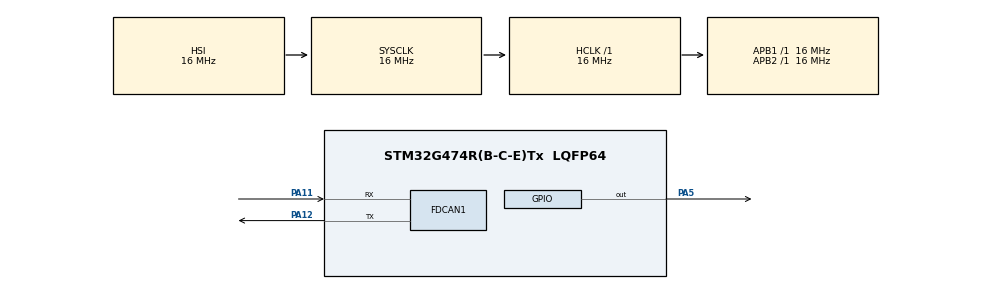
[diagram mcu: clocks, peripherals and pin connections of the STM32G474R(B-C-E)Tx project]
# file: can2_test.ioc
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FDCAN1.AutoRetransmission=ENABLE
FDCAN1.CalculateBaudRateNominal=250000
FDCAN1.CalculateTimeBitNominal=4000
FDCAN1.CalculateTimeQuantumNominal=125.0
FDCAN1.NominalPrescaler=2
FDCAN1.NominalSyncJumpWidth=4
FDCAN1.NominalTimeSeg1=25
FDCAN1.NominalTimeSeg2=6
FDCAN1.StdFiltersNbr=1
Mcu.Family=STM32G4
Mcu.Name=STM32G474R(B-C-E)Tx
Mcu.Package=LQFP64
NVIC.PriorityGroup=NVIC_PRIORITYGROUP_4
PA11.Mode=FDCAN_Activate
PA11.Signal=FDCAN1_RX
PA12.Mode=FDCAN_Activate
PA12.Signal=FDCAN1_TX
PA5.Signal=GPIO_Output
PA13.Mode=Serial_Wire
PA13.Signal=SYS_JTMS-SWDIO
PA14.Mode=Serial_Wire
PA14.Signal=SYS_JTCK-SWCLK
ProjectManager.HeapSize=0x200
ProjectManager.StackSize=0x400
ProjectManager.TargetToolchain=STM32CubeIDE
RCC.AHBFreq_Value=16000000
RCC.APB1Freq_Value=16000000
RCC.APB1TimFreq_Value=16000000
RCC.APB2Freq_Value=16000000
RCC.APB2TimFreq_Value=16000000
RCC.CortexFreq_Value=16000000
RCC.EXTERNAL_CLOCK_VALUE=12288000
RCC.HCLKFreq_Value=16000000
RCC.HSE_VALUE=8000000
RCC.HSI48_VALUE=48000000
RCC.HSI_VALUE=16000000
RCC.LSE_VALUE=32768
RCC.SYSCLKFreq_VALUE=16000000
RCC.USBFreq_Value=64000000
RCC.VCOOutputFreq_Value=128000000
VP_SYS_VS_DBSignals.Mode=DisableDeadBatterySignals
board=custom

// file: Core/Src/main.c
/* USER CODE BEGIN Header */
/**
  ******************************************************************************
  * @file           : main.c
  * @brief          : Main program body
  ******************************************************************************
  * @attention
  *
  * Copyright (c) 2026 STMicroelectronics.
  * All rights reserved.
  *
  * This software is licensed under terms that can be found in the LICENSE file
  * in the root directory of this software component.
  * If no LICENSE file comes with this software, it is provided AS-IS.
  *
  ******************************************************************************
  */
/* USER CODE END Header */
#include "main.h"

/* USER CODE BEGIN PD */
#define NODE_A  1  // G474 sends CAN pings to the F303.
/* USER CODE END PD */

FDCAN_HandleTypeDef hfdcan1;

/* USER CODE BEGIN PV */
volatile uint32_t canQueued = 0;
volatile uint32_t canCompleted = 0;
volatile uint32_t canLastError = 0;
volatile uint32_t canTxError = 0;
/* USER CODE END PV */

void SystemClock_Config(void);
static void MX_GPIO_Init(void);
static void MX_FDCAN1_Init(void);

int main(void)
{

  /* MCU Configuration--------------------------------------------------------*/

  /* Reset of all peripherals, Initializes the Flash interface and the Systick. */
  HAL_Init();

  /* Configure the system clock */
  SystemClock_Config();

  /* Initialize all configured peripherals */
  MX_GPIO_Init();
  MX_FDCAN1_Init();
  /* USER CODE BEGIN 2 */
  FDCAN_FilterTypeDef filter = {0};
  filter.IdType = FDCAN_STANDARD_ID;
  filter.FilterIndex = 0;
  filter.FilterType = FDCAN_FILTER_MASK;
  filter.FilterConfig = FDCAN_FILTER_TO_RXFIFO0;
  filter.FilterID1 = 0;
  filter.FilterID2 = 0;  // Accept all standard IDs

  if (HAL_FDCAN_ConfigFilter(&hfdcan1, &filter) != HAL_OK) Error_Handler();
  if (HAL_FDCAN_ConfigGlobalFilter(&hfdcan1,
          FDCAN_REJECT, FDCAN_REJECT,
          FDCAN_REJECT_REMOTE, FDCAN_REJECT_REMOTE) != HAL_OK) Error_Handler();
  if (HAL_FDCAN_Start(&hfdcan1) != HAL_OK) Error_Handler();

  FDCAN_TxHeaderTypeDef tx = {0};
  tx.IdType = FDCAN_STANDARD_ID;
  tx.TxFrameType = FDCAN_DATA_FRAME;
  tx.DataLength = FDCAN_DLC_BYTES_1;
  tx.ErrorStateIndicator = FDCAN_ESI_ACTIVE;
  tx.BitRateSwitch = FDCAN_BRS_OFF;
  tx.FDFormat = FDCAN_CLASSIC_CAN;
  tx.TxEventFifoControl = FDCAN_NO_TX_EVENTS;
  tx.MessageMarker = 0;

  uint8_t txData[1] = {0x55};
#if NODE_A
  uint32_t lastTx = HAL_GetTick();
#endif
  /* USER CODE END 2 */

  /* Infinite loop */
  while (1)
  {

    /* USER CODE BEGIN 3 */
#if NODE_A
if (HAL_GetTick() - lastTx >= 500) {
    lastTx = HAL_GetTick();
    tx.Identifier = 0x123;
    if (HAL_FDCAN_GetTxFifoFreeLevel(&hfdcan1) > 0) {
    	if (HAL_FDCAN_AddMessageToTxFifoQ(&hfdcan1, &tx, txData) == HAL_OK)
    	    canQueued++;
    }
}
#endif

if (HAL_FDCAN_GetRxFifoFillLevel(&hfdcan1, FDCAN_RX_FIFO0) > 0) {
    FDCAN_RxHeaderTypeDef rx;
    uint8_t rxData[8];

    if (HAL_FDCAN_GetRxMessage(&hfdcan1, FDCAN_RX_FIFO0,
                               &rx, rxData) == HAL_OK) {
#if NODE_A
        if (rx.Identifier == 0x124) {
            HAL_GPIO_TogglePin(GPIOA, GPIO_PIN_5); // Reply received from F303
        }
#else
        if (rx.Identifier == 0x123) {
            HAL_GPIO_TogglePin(GPIOA, GPIO_PIN_5); // Ping received
            tx.Identifier = 0x124;
            if (HAL_FDCAN_GetTxFifoFreeLevel(&hfdcan1) > 0) {
                HAL_FDCAN_AddMessageToTxFifoQ(&hfdcan1, &tx, txData);
            }
        }
#endif
    }
}
if (__HAL_FDCAN_GET_FLAG(&hfdcan1, FDCAN_FLAG_TX_COMPLETE)) {
    canCompleted++;
    __HAL_FDCAN_CLEAR_FLAG(&hfdcan1, FDCAN_FLAG_TX_COMPLETE);
}

FDCAN_ProtocolStatusTypeDef status;
FDCAN_ErrorCountersTypeDef errors;
if (HAL_FDCAN_GetProtocolStatus(&hfdcan1, &status) == HAL_OK)
    canLastError = status.LastErrorCode;
if (HAL_FDCAN_GetErrorCounters(&hfdcan1, &errors) == HAL_OK)
    canTxError = errors.TxErrorCnt;
HAL_Delay(1);
  }
  /* USER CODE END 3 */
}

void SystemClock_Config(void)
{
  RCC_OscInitTypeDef RCC_OscInitStruct = {0};
  RCC_ClkInitTypeDef RCC_ClkInitStruct = {0};

  /** Configure the main internal regulator output voltage
  */
  HAL_PWREx_ControlVoltageScaling(PWR_REGULATOR_VOLTAGE_SCALE1);

  /** Initializes the RCC Oscillators according to the specified parameters
  * in the RCC_OscInitTypeDef structure.
  */
  RCC_OscInitStruct.OscillatorType = RCC_OSCILLATORTYPE_HSI;
  RCC_OscInitStruct.HSIState = RCC_HSI_ON;
  RCC_OscInitStruct.HSICalibrationValue = RCC_HSICALIBRATION_DEFAULT;
  RCC_OscInitStruct.PLL.PLLState = RCC_PLL_NONE;
  if (HAL_RCC_OscConfig(&RCC_OscInitStruct) != HAL_OK)
  {
    Error_Handler();
  }

  /** Initializes the CPU, AHB and APB buses clocks
  */
  RCC_ClkInitStruct.ClockType = RCC_CLOCKTYPE_HCLK|RCC_CLOCKTYPE_SYSCLK
                              |RCC_CLOCKTYPE_PCLK1|RCC_CLOCKTYPE_PCLK2;
  RCC_ClkInitStruct.SYSCLKSource = RCC_SYSCLKSOURCE_HSI;
  RCC_ClkInitStruct.AHBCLKDivider = RCC_SYSCLK_DIV1;
  RCC_ClkInitStruct.APB1CLKDivider = RCC_HCLK_DIV1;
  RCC_ClkInitStruct.APB2CLKDivider = RCC_HCLK_DIV1;

  if (HAL_RCC_ClockConfig(&RCC_ClkInitStruct, FLASH_LATENCY_0) != HAL_OK)
  {
    Error_Handler();
  }
}

static void MX_FDCAN1_Init(void)
{

  hfdcan1.Instance = FDCAN1;
  hfdcan1.Init.ClockDivider = FDCAN_CLOCK_DIV1;
  hfdcan1.Init.FrameFormat = FDCAN_FRAME_CLASSIC;
  hfdcan1.Init.Mode = FDCAN_MODE_NORMAL;
  hfdcan1.Init.AutoRetransmission = ENABLE;
  hfdcan1.Init.TransmitPause = DISABLE;
  hfdcan1.Init.ProtocolException = DISABLE;
  hfdcan1.Init.NominalPrescaler = 2;
  hfdcan1.Init.NominalSyncJumpWidth = 4;
  hfdcan1.Init.NominalTimeSeg1 = 25;
  hfdcan1.Init.NominalTimeSeg2 = 6;
  hfdcan1.Init.DataPrescaler = 1;
  hfdcan1.Init.DataSyncJumpWidth = 1;
  hfdcan1.Init.DataTimeSeg1 = 1;
  hfdcan1.Init.DataTimeSeg2 = 1;
  hfdcan1.Init.StdFiltersNbr = 1;
  hfdcan1.Init.ExtFiltersNbr = 0;
  hfdcan1.Init.TxFifoQueueMode = FDCAN_TX_FIFO_OPERATION;
  if (HAL_FDCAN_Init(&hfdcan1) != HAL_OK)
  {
    Error_Handler();
  }

}

static void MX_GPIO_Init(void)
{

  /* GPIO Ports Clock Enable */
  __HAL_RCC_GPIOA_CLK_ENABLE();

  /* USER CODE BEGIN MX_GPIO_Init_2 */

  /* NUCLEO-G474RE user LED LD2 (PA5). */
  GPIO_InitTypeDef GPIO_InitStruct = {0};
  HAL_GPIO_WritePin(GPIOA, GPIO_PIN_5, GPIO_PIN_RESET);
  GPIO_InitStruct.Pin = GPIO_PIN_5;
  GPIO_InitStruct.Mode = GPIO_MODE_OUTPUT_PP;
  GPIO_InitStruct.Pull = GPIO_NOPULL;
  GPIO_InitStruct.Speed = GPIO_SPEED_FREQ_LOW;
  HAL_GPIO_Init(GPIOA, &GPIO_InitStruct);

  /* USER CODE END MX_GPIO_Init_2 */
}

void Error_Handler(void)
{
  __disable_irq();
  while (1)
  {
  }
}
